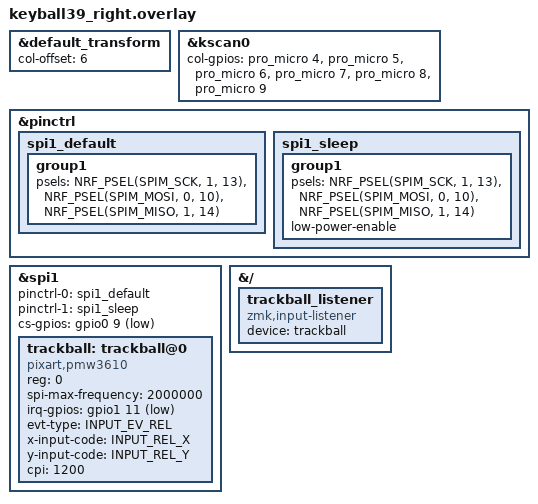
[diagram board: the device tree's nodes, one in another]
/* SPDX-License-Identifier: MIT */

#include "keyball39.dtsi"
#include <zephyr/dt-bindings/input/input-event-codes.h>

/* 右手は列オフセット 6 */
&default_transform {
    col-offset = <6>;
};

/* 右手の列配線 */
&kscan0 {
    col-gpios = <&pro_micro 4 GPIO_ACTIVE_HIGH>,
                <&pro_micro 5 GPIO_ACTIVE_HIGH>,
                <&pro_micro 6 GPIO_ACTIVE_HIGH>,
                <&pro_micro 7 GPIO_ACTIVE_HIGH>,
                <&pro_micro 8 GPIO_ACTIVE_HIGH>,
                <&pro_micro 9 GPIO_ACTIVE_HIGH>;
};

/* SPI ピン（MISO/MOSI/SCK は実配線に合わせて調整可） */
&pinctrl {
    spi1_default: spi1_default {
        group1 {
            psels = <NRF_PSEL(SPIM_SCK,  1, 13)>,
                    <NRF_PSEL(SPIM_MOSI, 0, 10)>,
                    <NRF_PSEL(SPIM_MISO, 1, 14)>;
        };
    };

    spi1_sleep: spi1_sleep {
        group1 {
            psels = <NRF_PSEL(SPIM_SCK,  1, 13)>,
                    <NRF_PSEL(SPIM_MOSI, 0, 10)>,
                    <NRF_PSEL(SPIM_MISO, 1, 14)>;
            low-power-enable;
        };
    };
};

&spi1 {
    status = "okay";
    pinctrl-0 = <&spi1_default>;
    pinctrl-1 = <&spi1_sleep>;
    pinctrl-names = "default", "sleep";
    cs-gpios = <&gpio0 9 GPIO_ACTIVE_LOW>;

    trackball: trackball@0 {
        status = "okay";
        compatible = "pixart,pmw3610";
        reg = <0>;
        spi-max-frequency = <2000000>;
        irq-gpios = <&gpio1 11 (GPIO_ACTIVE_LOW | GPIO_PULL_UP)>;

        /* binding 必須（相対移動のレポート） */
        evt-type     = <INPUT_EV_REL>;
        x-input-code = <INPUT_REL_X>;
        y-input-code = <INPUT_REL_Y>;

        /* 任意設定 */
        cpi = <1200>;      /* 200〜6400(200刻み) */
        /* swap-xy; */     /* 必要なら有効化 */
        /* invert-x; */    /* 180度相当にしたいなら x/y 両方有効化 */
        /* invert-y; */
        /* force-awake; */
        /* force-awake-4ms-mode; */
    };
};

/* 入力リスナー（そのままでOK） */
&{/} {
    trackball_listener {
        compatible = "zmk,input-listener";
        device = <&trackball>;
    };
};
